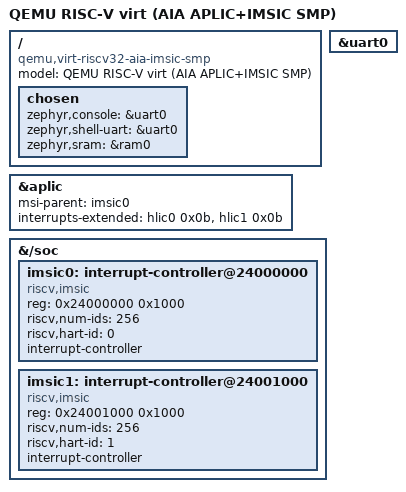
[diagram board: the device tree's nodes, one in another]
/*
 * SPDX-FileCopyrightText: Copyright The Zephyr Project Contributors
 *
 * SPDX-License-Identifier: Apache-2.0
 */

/dts-v1/;

#include <qemu/virt-riscv-aia.dtsi>

/ {
	model = "QEMU RISC-V virt (AIA APLIC+IMSIC SMP)";
	compatible = "qemu,virt-riscv32-aia-imsic-smp";

	chosen {
		zephyr,console = &uart0;
		zephyr,shell-uart = &uart0;
		zephyr,sram = &ram0;
	};
};

&uart0 {
	status = "okay";
};

&aplic {
	msi-parent = <&imsic0>;
	interrupts-extended = <&hlic0 0x0b &hlic1 0x0b>;
};

&{/soc} {
	/* IMSIC for hart 0 */
	imsic0: interrupt-controller@24000000 {
		compatible = "riscv,imsic";
		reg = <0x24000000 0x1000>;
		riscv,num-ids = <256>;
		riscv,hart-id = <0>;
		interrupt-controller;
		#interrupt-cells = <1>;
		status = "okay";
	};

	/* IMSIC for hart 1 */
	imsic1: interrupt-controller@24001000 {
		compatible = "riscv,imsic";
		reg = <0x24001000 0x1000>;
		riscv,num-ids = <256>;
		riscv,hart-id = <1>;
		interrupt-controller;
		#interrupt-cells = <1>;
		status = "okay";
	};
};
